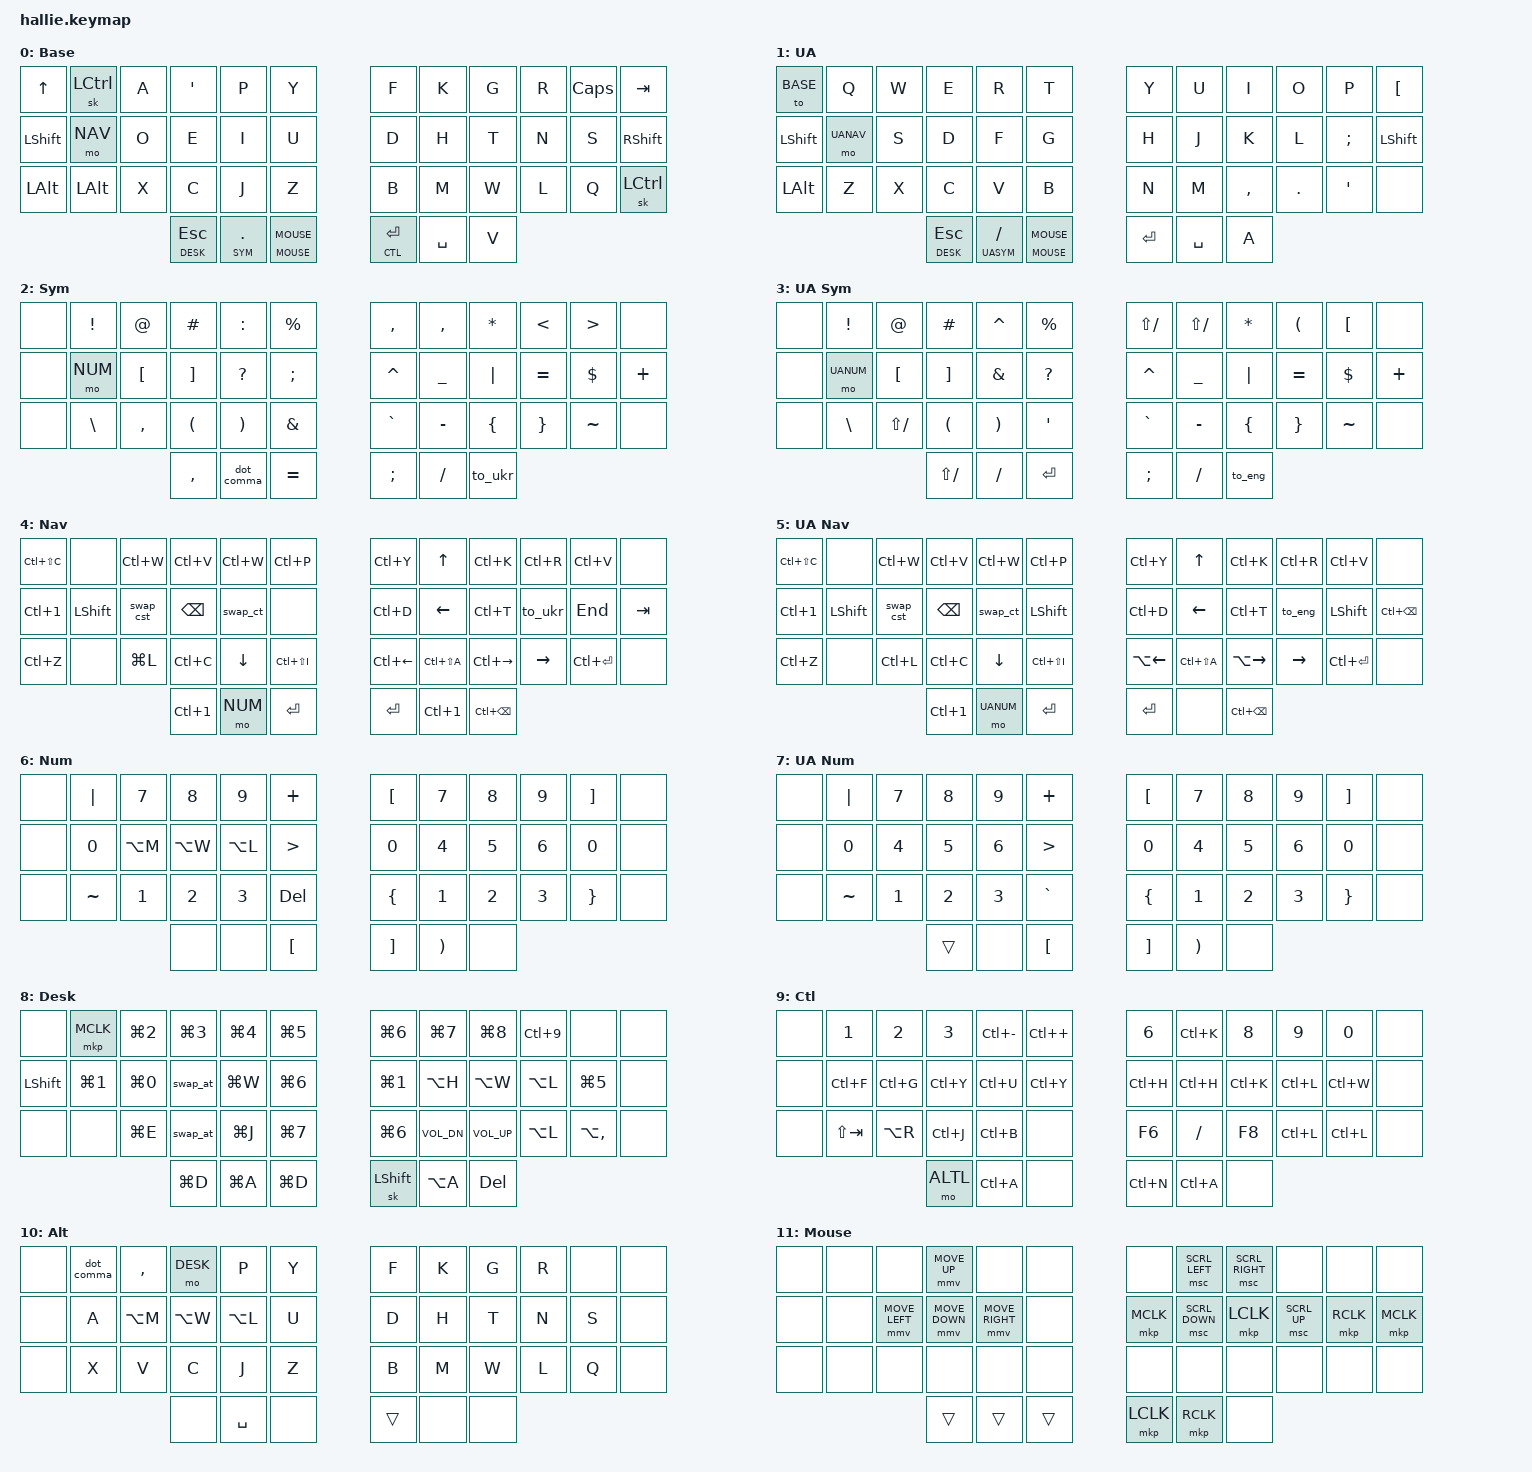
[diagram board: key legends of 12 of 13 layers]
#undef ZMK_BEHAVIORS_KEEP_ALL

#define ZMK_BEHAVIORS_KEEP_IND
#define ZMK_BEHAVIORS_KEEP_BT
#define ZMK_BEHAVIORS_KEEP_GRESC
#define ZMK_BEHAVIORS_KEEP_SYS_RESET
#define ZMK_BEHAVIORS_KEEP_BOOTLOADER
#define ZMK_BEHAVIORS_KEEP_CAPS_WORD
#define ZMK_BEHAVIORS_KEEP_KEY_REPEAT
#define ZMK_BEHAVIORS_KEEP_KT
#define ZMK_BEHAVIORS_KEEP_LT
#define ZMK_BEHAVIORS_KEEP_MT
#define ZMK_BEHAVIORS_KEEP_SK
#define ZMK_BEHAVIORS_KEEP_STICKY_LAYER
#define ZMK_BEHAVIORS_KEEP_TO
#define ZMK_BEHAVIORS_KEEP_TOG
#define ZMK_BEHAVIORS_KEEP_TRANS
#define ZMK_BEHAVIORS_KEEP_MKP
#define ZMK_BEHAVIORS_KEEP_MMV
#define ZMK_BEHAVIORS_KEEP_MSC

#include <behaviors.dtsi>
#include <behaviors/indicators.dtsi>

#include <dt-bindings/zmk/bt.h>
#include <dt-bindings/zmk/keys.h>
#include <dt-bindings/zmk/outputs.h>
#include <dt-bindings/zmk/pointing.h>
#include <dt-bindings/zmk/indicators.h>

/* Gentler scroll on the mouse layer's held scroll keys (default 10).
 * Do not go below ~6: the per-tick movement rounds down to zero and
 * scrolling dies entirely. */
#undef ZMK_POINTING_DEFAULT_SCRL_VAL
#define ZMK_POINTING_DEFAULT_SCRL_VAL 8

/*
 * Layer order matters: ZMK resolves overlapping active layers from the
 * highest index down, so layers reached via &mo from another layer must
 * sit above that layer (NUM > SYM/NAV, UANUM > UASYM/UANAV, ALTL > CTL,
 * SET above everything).
 */
#define BASE  0
#define UA    1
#define SYM   2
#define UASYM 3
#define NAV   4
#define UANAV 5
#define NUM   6
#define UANUM 7
#define DESK  8
#define CTL   9
#define ALTL  10
#define MOUSE 11
#define SET   12

/* Replicates the QMK tap/hold feel: any other key during the hold commits
 * to the layer; an uninterrupted release sends the tap even after the term. */
&lt {
    quick-tap-ms = <200>;
    tapping-term-ms = <200>;
    flavor = "hold-preferred";
    retro-tap;
};

&mt { quick-tap-ms = <200>; };

/ {
    /* Half the stock 18: the encoder fires one (stock-strength) scroll
     * event per two detents — half speed without touching the fragile
     * per-event value. */
    sensors {
        triggers-per-rotation = <9>;
    };

    behaviors {
        /* Ctrl+Tab cycling: Ctrl goes down on first press and stays down
         * across repeats; releasing the nav-layer thumb (pos 13) or any
         * unrelated key ends the cycle and releases Ctrl. Only the two
         * cycle keys (14/16) and pos 17 stay transparent to the cycle. */
        swap_ct: swap_ct {
            compatible = "zmk,behavior-tri-state";
            #binding-cells = <0>;
            bindings = <&ctl_dn>, <&tab_tap>, <&ctl_up>;
            ignored-key-positions = <14 16 17>;
        };

        swap_cst: swap_cst {
            compatible = "zmk,behavior-tri-state";
            #binding-cells = <0>;
            bindings = <&ctl_dn>, <&stab_tap>, <&ctl_up>;
            ignored-key-positions = <14 16 17>;
        };

        /* Inner tall thumb: hold = mouse layer while held (original QMK
         * feel), tap = toggle the mouse layer on/off. The settings
         * layer moved to the two-thumb chord defined in combos below. */
        smt: smt {
            compatible = "zmk,behavior-hold-tap";
            #binding-cells = <2>;
            flavor = "hold-preferred";
            tapping-term-ms = <200>;
            bindings = <&mo>, <&tog>;
        };

        /* Alt+Tab swapper on the desk layer: Alt stays held across
         * repeated presses; releasing the desk thumb (or pressing any
         * other key) releases Alt and commits the selection. */
        swap_at: swap_at {
            compatible = "zmk,behavior-tri-state";
            #binding-cells = <0>;
            bindings = <&alt_dn>, <&tab_tap>, <&alt_up>;
        };

        /* Shift+. types a comma (shift suppressed), like the old QMK trick. */
        dot_comma: dot_comma {
            compatible = "zmk,behavior-mod-morph";
            #binding-cells = <0>;
            bindings = <&kp DOT>, <&kp COMMA>;
            mods = <(MOD_LSFT|MOD_RSFT)>;
        };
    };

    combos {
        compatible = "zmk,combos";

        /* Settings layer: hold BOTH tall inner thumb keys (positions
         * 38 + 39). While held, the settings layer is active — tap the
         * documented keys for BT channels, bootloader (Z position =
         * left half, / position on the right half = right half), etc.
         * require-prior-idle prevents accidental triggers when rolling
         * Enter into the mouse thumb during normal typing. */
        combo_settings {
            timeout-ms = <40>;
            key-positions = <38 39>;
            bindings = <&mo SET>;
            require-prior-idle-ms = <100>;
        };
    };

    macros {
        /* Swapper parts. The modifier is held by the tri-state's
         * start behavior and released by its end behavior — explicit
         * press/release, never &kt (a toggle reads the live modifier
         * state, which races the asynchronous behavior queue and can
         * release Alt right before Tab, sending a bare Tab).
         *
         * alt_dn/ctl_dn carry wait-ms so the queue pauses after the
         * modifier lands before the Tab that follows it — laggy hosts
         * (RDP) otherwise process Tab before the modifier. 40 ms cut
         * the failures down but did not eliminate them; 90 ms is the
         * current setting. tab_tap's trailing wait-ms keeps the
         * modifier release out of the same input batch as the Tab. */
        alt_dn: alt_dn {
            compatible = "zmk,behavior-macro";
            #binding-cells = <0>;
            wait-ms = <90>;
            bindings = <&macro_press &kp LALT>;
        };

        alt_up: alt_up {
            compatible = "zmk,behavior-macro";
            #binding-cells = <0>;
            bindings = <&macro_release &kp LALT>;
        };

        ctl_dn: ctl_dn {
            compatible = "zmk,behavior-macro";
            #binding-cells = <0>;
            wait-ms = <90>;
            bindings = <&macro_press &kp LCTRL>;
        };

        ctl_up: ctl_up {
            compatible = "zmk,behavior-macro";
            #binding-cells = <0>;
            bindings = <&macro_release &kp LCTRL>;
        };

        /* Cycle steps: no modifier handling at all. */
        tab_tap: tab_tap {
            compatible = "zmk,behavior-macro";
            #binding-cells = <0>;
            tap-ms = <30>;
            wait-ms = <40>;
            bindings = <&macro_tap &kp TAB>;
        };

        /* Shift is momentary per step, balanced inside this macro. */
        stab_tap: stab_tap {
            compatible = "zmk,behavior-macro";
            #binding-cells = <0>;
            wait-ms = <40>;
            tap-ms = <30>;
            bindings
                = <&macro_press &kp LSHFT>
                , <&macro_tap &kp TAB>
                , <&macro_release &kp LSHFT>;
        };

        /* Security screen. Ctrl+Alt+Del is intercepted by the local
         * machine even inside an RDP window (it is the Secure Attention
         * Sequence); Ctrl+Alt+End is the RDP-session equivalent. Paced
         * and balanced like the other chords so laggy hosts see the
         * modifiers before the key. */
        cad: cad {
            compatible = "zmk,behavior-macro";
            #binding-cells = <0>;
            wait-ms = <40>;
            tap-ms = <40>;
            bindings
                = <&macro_press &kp LCTRL>
                , <&macro_press &kp LALT>
                , <&macro_tap &kp DEL>
                , <&macro_release &kp LALT>
                , <&macro_release &kp LCTRL>;
        };

        cae: cae {
            compatible = "zmk,behavior-macro";
            #binding-cells = <0>;
            wait-ms = <40>;
            tap-ms = <40>;
            bindings
                = <&macro_press &kp LCTRL>
                , <&macro_press &kp LALT>
                , <&macro_tap &kp END>
                , <&macro_release &kp LALT>
                , <&macro_release &kp LCTRL>;
        };

        /* Absolute OS language selection + layer switch. Matches the
         * hotkeys assigned in Windows "Input language hot keys":
         * Ctrl+Shift+2 = English, Ctrl+Shift+3 = Ukrainian. Unlike the
         * Alt+Shift toggle these cannot drift out of sync: each key
         * always lands on its language no matter what state the OS is
         * in.
         *
         * Human-paced chords: mods land well before the digit and are
         * released well after, so laggy hosts (RDP) can't miss the
         * modifier state the way they do with a single-report chord. */
        to_ukr: to_ukr {
            compatible = "zmk,behavior-macro";
            #binding-cells = <0>;
            wait-ms = <40>;
            tap-ms = <40>;
            bindings
                = <&macro_press &kp LCTRL>
                , <&macro_press &kp LSHFT>
                , <&macro_tap &kp N3>
                , <&macro_release &kp LSHFT>
                , <&macro_release &kp LCTRL>
                , <&macro_tap &to UA>;
        };

        to_eng: to_eng {
            compatible = "zmk,behavior-macro";
            #binding-cells = <0>;
            wait-ms = <40>;
            tap-ms = <40>;
            bindings
                = <&macro_press &kp LCTRL>
                , <&macro_press &kp LSHFT>
                , <&macro_tap &kp N2>
                , <&macro_release &kp LSHFT>
                , <&macro_release &kp LCTRL>
                , <&macro_tap &to BASE>;
        };
    };

    keymap {
        compatible = "zmk,keymap";

        base_layer {
            display-name = "Base";
            bindings = <
&kp UP     &sk LCTRL  &kp A  &kp SQT  &kp P  &kp Y    &kp F  &kp K  &kp G  &kp R  &kp CAPS  &kp TAB
&kp LSHFT  &mo NAV    &kp O  &kp E    &kp I  &kp U    &kp D  &kp H  &kp T  &kp N  &kp S     &kp RSHFT
&kp LALT   &kp LALT   &kp X  &kp C    &kp J  &kp Z    &kp B  &kp M  &kp W  &kp L  &kp Q     &sk LCTRL
             &lt DESK ESC  &lt SYM DOT  &smt MOUSE MOUSE    &lt CTL RET  &kp SPACE  &kp V
            >;

            sensor-bindings = <&inc_dec_kp C_VOL_DN C_VOL_UP &scroll_u_d>;
        };

        ua_layer {
            display-name = "UA";
            bindings = <
&to BASE   &kp Q      &kp W  &kp E  &kp R  &kp T    &kp Y  &kp U  &kp I      &kp O    &kp P     &kp LBKT
&kp LSHFT  &mo UANAV  &kp S  &kp D  &kp F  &kp G    &kp H  &kp J  &kp K      &kp L    &kp SEMI  &kp LSHFT
&kp LALT   &kp Z      &kp X  &kp C  &kp V  &kp B    &kp N  &kp M  &kp COMMA  &kp DOT  &kp SQT   &none
             &lt DESK ESC  &lt UASYM FSLH  &smt MOUSE MOUSE    &kp RET  &kp SPACE  &kp A
            >;

            sensor-bindings = <&inc_dec_kp C_VOL_DN C_VOL_UP &scroll_u_d>;
        };

        sym_layer {
            display-name = "Sym";
            bindings = <
&none  &kp EXCL  &kp AT     &kp HASH  &kp COLON  &kp PRCNT    &kp COMMA  &kp COMMA  &kp ASTRK  &kp LT     &kp GT     &none
&none  &mo NUM   &kp LBKT   &kp RBKT  &kp QMARK  &kp SEMI     &kp CARET  &kp UNDER  &kp PIPE   &kp EQUAL  &kp DLLR   &kp PLUS
&none  &kp BSLH  &kp COMMA  &kp LPAR  &kp RPAR   &kp AMPS     &kp GRAVE  &kp MINUS  &kp LBRC   &kp RBRC   &kp TILDE  &none
             &kp COMMA  &dot_comma  &kp EQUAL    &kp SEMI  &kp FSLH  &to_ukr
            >;
        };

        ua_sym_layer {
            display-name = "UA Sym";
            bindings = <
&none  &kp EXCL   &kp AT        &kp HASH  &kp CARET  &kp PRCNT    &kp LS(FSLH)  &kp LS(FSLH)  &kp ASTRK  &kp LPAR   &kp LBKT   &none
&none  &mo UANUM  &kp LBKT      &kp RBKT  &kp AMPS   &kp QMARK    &kp CARET     &kp UNDER     &kp PIPE   &kp EQUAL  &kp DLLR   &kp PLUS
&none  &kp BSLH   &kp LS(FSLH)  &kp LPAR  &kp RPAR   &kp SQT      &kp GRAVE     &kp MINUS     &kp LBRC   &kp RBRC   &kp TILDE  &none
             &kp LS(FSLH)  &kp FSLH  &kp RET    &kp SEMI  &kp FSLH  &to_eng
            >;
        };

        nav_layer {
            display-name = "Nav";
            bindings = <
&kp LC(LS(C))  &none      &kp LC(W)  &kp LC(V)  &kp LC(W)  &kp LC(P)        &kp LC(Y)     &kp UP         &kp LC(K)      &kp LC(R)  &kp LC(V)    &none
&kp LC(N1)     &kp LSHFT  &swap_cst  &kp BSPC   &swap_ct   &none            &kp LC(D)     &kp LEFT       &kp LC(T)      &to_ukr    &kp END      &kp TAB
&kp LC(Z)      &none      &kp LG(L)  &kp LC(C)  &kp DOWN   &kp LC(LS(I))    &kp LC(LEFT)  &kp LC(LS(A))  &kp LC(RIGHT)  &kp RIGHT  &kp LC(RET)  &none
             &kp LC(N1)  &mo NUM  &kp RET    &kp RET  &kp LC(N1)  &kp LC(BSPC)
            >;
        };

        ua_nav_layer {
            display-name = "UA Nav";
            bindings = <
&kp LC(LS(C))  &none      &kp LC(W)  &kp LC(V)  &kp LC(W)  &kp LC(P)        &kp LC(Y)     &kp UP         &kp LC(K)      &kp LC(R)  &kp LC(V)    &none
&kp LC(N1)     &kp LSHFT  &swap_cst  &kp BSPC   &swap_ct   &kp LSHFT        &kp LC(D)     &kp LEFT       &kp LC(T)      &to_eng    &kp LSHFT    &kp LC(BSPC)
&kp LC(Z)      &none      &kp LC(L)  &kp LC(C)  &kp DOWN   &kp LC(LS(I))    &kp LA(LEFT)  &kp LC(LS(A))  &kp LA(RIGHT)  &kp RIGHT  &kp LC(RET)  &none
             &kp LC(N1)  &mo UANUM  &kp RET    &kp RET  &none  &kp LC(BSPC)
            >;
        };

        num_layer {
            display-name = "Num";
            bindings = <
&none  &kp PIPE   &kp N7     &kp N8     &kp N9     &kp PLUS    &kp LBKT  &kp N7  &kp N8  &kp N9  &kp RBKT  &none
&none  &kp N0     &kp LA(M)  &kp LA(W)  &kp LA(L)  &kp GT      &kp N0    &kp N4  &kp N5  &kp N6  &kp N0    &none
&none  &kp TILDE  &kp N1     &kp N2     &kp N3     &kp DEL     &kp LBRC  &kp N1  &kp N2  &kp N3  &kp RBRC  &none
             &none  &none  &kp LBKT    &kp RBKT  &kp RPAR  &none
            >;
        };

        ua_num_layer {
            display-name = "UA Num";
            bindings = <
&none  &kp PIPE   &kp N7  &kp N8  &kp N9  &kp PLUS     &kp LBKT  &kp N7  &kp N8  &kp N9  &kp RBKT  &none
&none  &kp N0     &kp N4  &kp N5  &kp N6  &kp GT       &kp N0    &kp N4  &kp N5  &kp N6  &kp N0    &none
&none  &kp TILDE  &kp N1  &kp N2  &kp N3  &kp GRAVE    &kp LBRC  &kp N1  &kp N2  &kp N3  &kp RBRC  &none
             &trans  &none  &kp LBKT    &kp RBKT  &kp RPAR  &none
            >;
        };

        desk_layer {
            display-name = "Desk";
            bindings = <
&none      &mkp MCLK   &kp LG(N2)  &kp LG(N3)  &kp LG(N4)  &kp LG(N5)    &kp LG(N6)  &kp LG(N7)    &kp LG(N8)    &kp LC(N9)  &none          &none
&kp LSHFT  &kp LG(N1)  &kp LG(N0)  &swap_at    &kp LG(W)   &kp LG(N6)    &kp LG(N1)  &kp LA(H)     &kp LA(W)     &kp LA(L)   &kp LG(N5)     &none
&none      &none       &kp LG(E)   &swap_at    &kp LG(J)   &kp LG(N7)    &kp LG(N6)  &kp C_VOL_DN  &kp C_VOL_UP  &kp LA(L)   &kp LA(COMMA)  &none
             &kp LG(D)  &kp LG(A)  &kp LG(D)    &sk LSHFT  &kp LA(A)  &kp DEL
            >;
        };

        ctl_layer {
            display-name = "Ctl";
            bindings = <
&none  &kp N1       &kp N2     &kp N3     &kp LC(MINUS)  &kp LC(PLUS)    &kp N6     &kp LC(K)  &kp N8     &kp N9     &kp N0     &none
&none  &kp LC(F)    &kp LC(G)  &kp LC(Y)  &kp LC(U)      &kp LC(Y)       &kp LC(H)  &kp LC(H)  &kp LC(K)  &kp LC(L)  &kp LC(W)  &none
&none  &kp LS(TAB)  &kp LA(R)  &kp LC(J)  &kp LC(B)      &none           &kp F6     &kp FSLH   &kp F8     &kp LC(L)  &kp LC(L)  &none
             &mo ALTL  &kp LC(A)  &none    &kp LC(N)  &kp LC(A)  &none
            >;
        };

        alt_layer {
            display-name = "Alt";
            bindings = <
&none  &dot_comma  &kp COMMA  &mo DESK   &kp P      &kp Y    &kp F  &kp K  &kp G  &kp R  &none  &none
&none  &kp A       &kp LA(M)  &kp LA(W)  &kp LA(L)  &kp U    &kp D  &kp H  &kp T  &kp N  &kp S  &none
&none  &kp X       &kp V      &kp C      &kp J      &kp Z    &kp B  &kp M  &kp W  &kp L  &kp Q  &none
             &none  &kp SPACE  &none    &trans  &none  &none
            >;
        };

        mouse_layer {
            display-name = "Mouse";
            bindings = <
&none  &none  &none           &mmv MOVE_UP    &none            &none    &none      &msc SCRL_LEFT  &msc SCRL_RIGHT  &none         &none      &none
&none  &none  &mmv MOVE_LEFT  &mmv MOVE_DOWN  &mmv MOVE_RIGHT  &none    &mkp MCLK  &msc SCRL_DOWN  &mkp LCLK        &msc SCRL_UP  &mkp RCLK  &mkp MCLK
&none  &none  &none           &none           &none            &none    &none      &none           &none            &none         &none      &none
             &trans  &trans  &trans    &mkp LCLK  &mkp RCLK  &none
            >;
        };

        settings_layer {
            display-name = "Settings";
            bindings = <
&out OUT_BLE  &bt BT_SEL 0  &bt BT_SEL 1  &bt BT_SEL 2    &bt BT_CLR   &out OUT_USB    &none        &none        &none  &none  &none  &none
&none         &none         &none         &cad            &cae         &none           &none        &none        &none  &none  &none  &none
&sys_reset    &bootloader   &none         &studio_unlock  &ind IND_ON  &ind BAT_ST     &ind IND_ON  &ind BAT_ST  &none  &none  &bootloader  &sys_reset
             &none  &none  &none    &none  &none  &none
            >;

            sensor-bindings = <&inc_dec_kp DOWN_ARROW UP_ARROW &inc_dec_kp RIGHT_ARROW LEFT_ARROW>;
        };

        extra1 { status = "reserved"; };

        extra2 { status = "reserved"; };
    };
};
